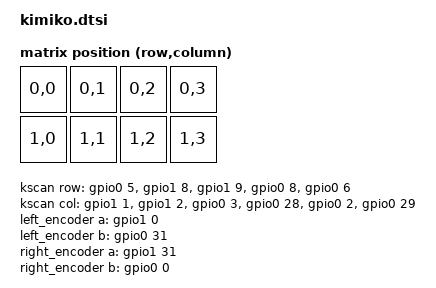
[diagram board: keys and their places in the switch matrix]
// This file was generated from a template. Edit it to match your keyboard.
// See https://zmk.dev/docs/development/hardware-integration/new-shield for more
// instructions.

#include <dt-bindings/zmk/matrix_transform.h>

#include "kimiko-layouts.dtsi"

/ {
    chosen {
        zmk,physical-layout = &default_layout;
        zephyr,display = &oled;
        zmk,kscan = &kscan0;
    };

    kscan: kscan {
        // If the hardware does not use a switch matrix, change this to the
        // appropriate driver and update the properties below to match.
        // See https://zmk.dev/docs/config/kscan for supported key scan drivers.
        compatible = "zmk,kscan-gpio-matrix";
        // Set this to "col2row" or "row2col" to match the hardware. If using
        // "row2col", change the col-gpios in the _left.overlay and _right.overlay
        // files to (GPIO_ACTIVE_HIGH | GPIO_PULL_DOWN) and the row-gpios here to
        // GPIO_ACTIVE_HIGH.
        wakeup-source;
        diode-direction = "col2row";

        // Replace these comments with the GPIO pins in the matrix.
        // See https://zmk.dev/docs/development/hardware-integration/new-shield#shield-overlays
        row-gpios = 
        <&gpio0 5 GPIO_ACTIVE_HIGH>,
        <&gpio1 8 GPIO_ACTIVE_HIGH>,
        <&gpio1 9 GPIO_ACTIVE_HIGH>,
        <&gpio0 8 GPIO_ACTIVE_HIGH>,
        <&gpio0 6 GPIO_ACTIVE_HIGH>;
        col-gpios = 
        <&gpio1 1 GPIO_ACTIVE_HIGH>,
        <&gpio1 2 GPIO_ACTIVE_HIGH>,
        <&gpio0 3 GPIO_ACTIVE_HIGH>,
        <&gpio0 28 GPIO_ACTIVE_HIGH>,
        <&gpio0 2 GPIO_ACTIVE_HIGH>,
        <&gpio0 29 GPIO_ACTIVE_HIGH>;
};


left_encoder: encoder_left {
    compatible = "alps,ec11";
    a-gpios = <&gpio1 0 GPIO_ACTIVE_HIGH>;
    b-gpios = <&gpio0 31 GPIO_ACTIVE_HIGH>;
    steps = <80>;
    status = "enabled";
};

right_encoder: encoder_right {
    compatible = "alps,ec11";
    a-gpios = <&gpio1 31 GPIO_ACTIVE_HIGH>;
    b-gpios = <&gpio0 0 GPIO_ACTIVE_HIGH>;
    steps = <80>;
    status = "enabled";
};

led_strip: led_strip {
    compatible = "zmk,led-strip";
    label = "LED_STRIP";
    data-gpios = <&gpio0 20 GPIO_ACTIVE_HIGH>;
    chain-length = <30>;
};

    default_transform: default_transform {
        // See https://zmk.dev/docs/development/hardware-integration/new-shield#matrix-transform
        // for how to configure this
        compatible = "zmk,matrix-transform";
        columns = <4>;
        rows = <2>;

        map = <
            RC(0, 0) RC(0, 1)    RC(0, 2) RC(0, 3)
            RC(1, 0) RC(1, 1)    RC(1, 2) RC(1, 3)
        >;
    };
};
